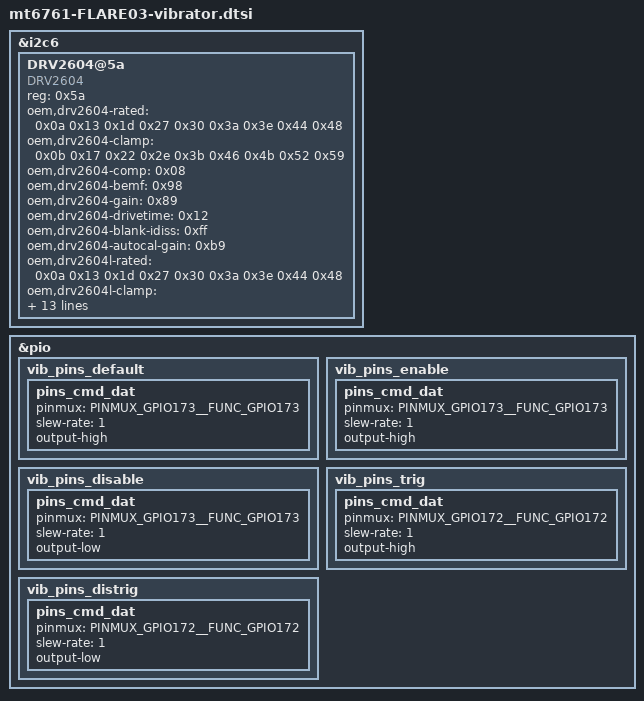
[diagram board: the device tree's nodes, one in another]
/*
 * This software is contributed or developed by KYOCERA Corporation.
 * (C) 2022 KYOCERA Corporation
 *
 * This program is free software; you can redistribute it and/or modify
 * it under the terms of the GNU General Public License version 2 and
 * only version 2 as published by the Free Software Foundation.
 *
 * This program is distributed in the hope that it will be useful,
 * but WITHOUT ANY WARRANTY; without even the implied warranty of
 * MERCHANTABILITY or FITNESS FOR A PARTICULAR PURPOSE.  See the
 * GNU General Public License for more details.
 */

&i2c6 {
	DRV2604@5a {
		compatible = "DRV2604";
		reg = <0x5a>;
		oem,drv2604-rated = <0x0a 0x13 0x1d 0x27 0x30 0x3a 0x3e 0x44 0x48>;
		oem,drv2604-clamp = <0x0b 0x17 0x22 0x2e 0x3b 0x46 0x4b 0x52 0x59>;
		oem,drv2604-comp = <0x08>;
		oem,drv2604-bemf = <0x98>;
		oem,drv2604-gain = <0x89>;
		oem,drv2604-drivetime = <0x12>;
		oem,drv2604-blank-idiss = <0xff>;
		oem,drv2604-autocal-gain = <0xb9>;
		oem,drv2604l-rated = <0x0a 0x13 0x1d 0x27 0x30 0x3a 0x3e 0x44 0x48>;
		oem,drv2604l-clamp = <0x0b 0x17 0x22 0x2e 0x3b 0x46 0x4b 0x52 0x59>;
		oem,drv2604l-comp = <0x07>;
		oem,drv2604l-bemf = <0x88>;
		oem,drv2604l-gain = <0x89>;
		oem,drv2604l-drivetime = <0x12>;
		oem,drv2604l-blank-idiss = <0xff>;
		oem,drv2604l-ext-blank-idiss = <0x0f>;
		oem,drv2604l-autocal-gain = <0xb9>;
		pinctrl-names = "default", "vib_enable_pin", "vib_disable_pin",
			"vib_trig_pin", "vib_distrig_pin";
		pinctrl-0 = <&vib_pins_default>;
		pinctrl-1 = <&vib_pins_enable>;
		pinctrl-2 = <&vib_pins_disable>;
		pinctrl-3 = <&vib_pins_trig>;
		pinctrl-4 = <&vib_pins_distrig>;
	};
};

&pio {
	vib_pins_default: vib_pins_default {
				pins_cmd_dat {
					pinmux = <PINMUX_GPIO173__FUNC_GPIO173>;
					slew-rate = <1>;
					output-high;
				};
	};
	vib_pins_enable: vib_pins_enable {
				pins_cmd_dat {
					pinmux = <PINMUX_GPIO173__FUNC_GPIO173>;
					slew-rate = <1>;
					output-high;
				};
	};
	vib_pins_disable: vib_pins_disable {
				pins_cmd_dat {
					pinmux = <PINMUX_GPIO173__FUNC_GPIO173>;
					slew-rate = <1>;
					output-low;
				};
	};
	vib_pins_trig: vib_pins_trig {
				pins_cmd_dat {
					pinmux = <PINMUX_GPIO172__FUNC_GPIO172>;
					slew-rate = <1>;
					output-high;
				};
	};
	vib_pins_distrig: vib_pins_distrig {
				pins_cmd_dat {
					pinmux = <PINMUX_GPIO172__FUNC_GPIO172>;
					slew-rate = <1>;
					output-low;
				};
	};
};
